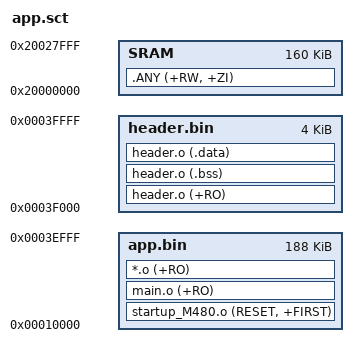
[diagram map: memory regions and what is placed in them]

LOAD_ROM_1  0x10000 0x2F000
{
	app.bin  0x10000 0x2F000
	{
		startup_M480.o (RESET, +FIRST)
		main.o (+RO)
		*.o (+RO)
		;ANY(+RO)
	}
	
	SRAM  0x20000000 0x28000
	{
		.ANY (+RW, +ZI)
	}
}

LOAD_ROM_2  0x3F000 0x1000
{
	header.bin  0x3F000 0x1000
	{
		header.o (+RO)
		header.o (.bss)
		header.o (.data)
	}
}



